# YTM32B1MD2 register map
Vendor: YTMicro; File version: 1.0
CPU: CM33 r0p4, little endian, MPU, FPU, 2 interrupt priority bits
Registers are 32-bit, read-write, reset 0x0 unless marked. A register's access mark holds for its fields unless they carry their own. Offsets are from the block's base; [hi:lo] are bit positions; {n}, {i} and the like mark numbered series.

## MPWM0 — Multiple Pulse Width Modulation
Base 0x4004F000; register names take the prefix MPWM0_
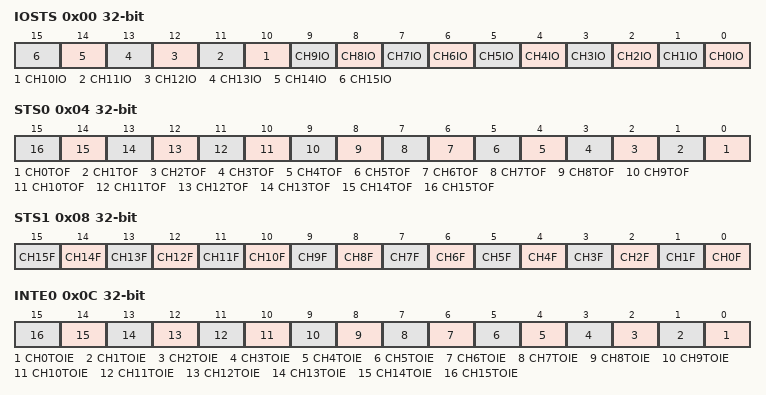
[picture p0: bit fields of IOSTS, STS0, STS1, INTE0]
0x00 IOSTS ro
  [all] fields
    0=Channel status is 0; 1=Channel status is 1
  [n] CH{n}IO (n=0..15) — Indicate channel {n} input/output status in pwm mode, compare mode and input capture mode. This bit is read only and the write operation is invalid.
0x04 STS0
  [all] fields
    0=No timer overflow event occurs; 1=Timer overflow event occurs
  [n] CH{n}TOF (n=0..15) — Indicate channel {n} timer overflow flag. Write 1 to clear the bit.
0x08 STS1
  [all] fields
    0=No channel event occurs; 1=Channel event occurs
  [n] CH{n}F (n=0..15) — Indicate channel {n} matching event flag in common timer mode, pwm mode, compare mode and pulse counter mode. Indicate channel {n} capture event flag in input capture mode. Write 1 to clear the bit.
0x0C INTE0
  [n] CH{n}TOIE (n=0..15) — Channel {n} timer overflow interrupt enable/disable.
    0=Channel {n} timer overflow interrupt is disabled; 1=Channel {n} timer overflow interrupt is enabled
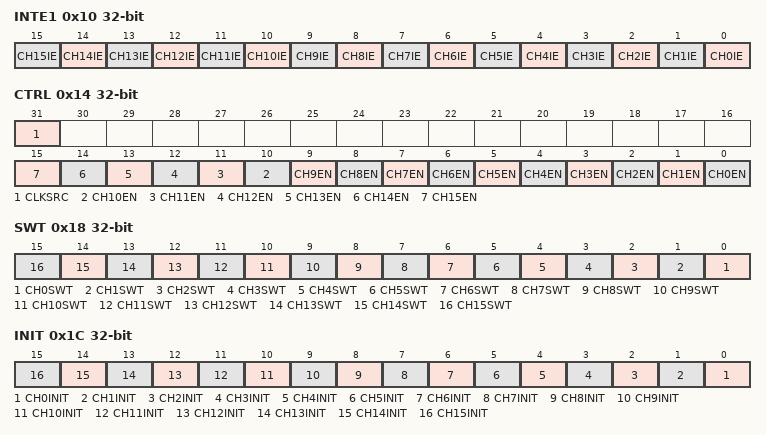
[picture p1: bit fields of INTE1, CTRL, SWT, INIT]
0x10 INTE1
  [n] CH{n}IE (n=0..15) — Channel {n} interrupt enable/disable.
    0=Channel {n} interrupt is disabled; 1=Channel {n} interrupt is enabled
0x14 CTRL
  [31] CLKSRC — Select MPWM works in function clock or bus clock domain.
    0=Using bus clock as the MPWM module clock source; 1=Using function clock(from IPC) as the MPWM module clock source
  [n] CH{n}EN (n=0..15) — Channel {n} enable/disable.
    0=Channel {n} is disabled; 1=Channel {n} is enabled
0x18 SWT wo
  [n] CH{n}SWT (n=0..15) — Channel {n} software trigger by writing 1 to this bit and keep a bus clock cycle. The bit is write only. Read operation is invalid and always returns 0.
0x1C INIT
  [n] CH{n}INIT (n=0..15) — Channel {n} initial value in PWM mode and compare mode before Channel {n} is enabled.
    0=Channel {n} initial value is 0; 1=Channel {n} initial value is 1
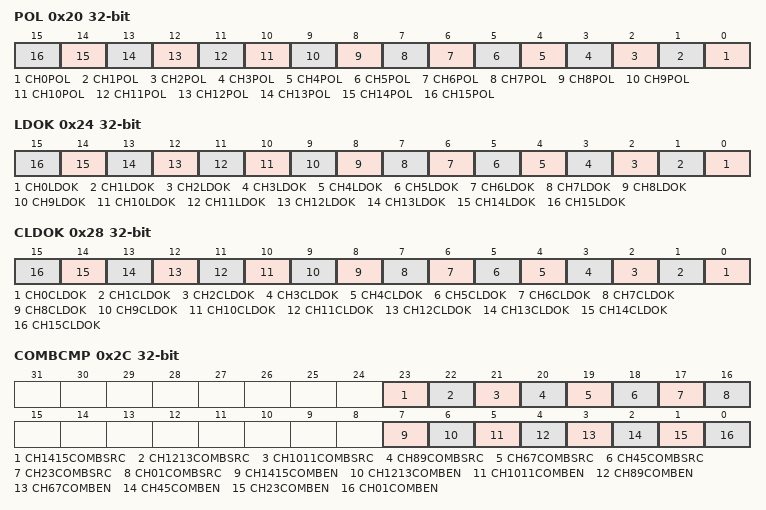
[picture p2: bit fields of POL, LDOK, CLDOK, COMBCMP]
0x20 POL
  [n] CH{n}POL (n=0..15) — Channel {n} polarity in PWM mode and compare mode.
    0=Not invert the channel {n} output; 1=Invert the channel {n} output
0x24 LDOK
  [all] fields
    0=Registers is not ready for loading; 1=Registers is ready for loading and wait for loading opportunity
  [n] CH{n}LDOK (n=0..15) — Set CH{n}LDOK to indicate registers(CMP and PERIOD) is ready for loading, it is cleared automatically when registers load successfully.
0x28 CLDOK
  [n] CH{n}CLDOK (n=0..15) — Write 1 to this bit to clear CH{n}LDOK, and it automatically clear when CH{n}LDOK=0.
0x2C COMBCMP
  [23] CH1415COMBSRC — When CH1415COMBSRC=0, select channel 14 as combination capture input source. When CH1415COMBSRC=1, select channel 15 as combination capture input source.
  [22] CH1213COMBSRC — When CH1213COMBSRC=0, select channel 12 as combination capture input source. When CH1213COMBSRC=1, select channel 13 as combination capture input source.
  [21] CH1011COMBSRC — When CH1011COMBSRC=0, select channel 10 as combination capture input source. When CH1011COMBSRC=1, select channel 11 as combination capture input source.
  [20] CH89COMBSRC — When CH89COMBSRC=0, select channel 8 as combination capture input source. When CH89COMBSRC=1, select channel 9 as combination capture input source.
  [19] CH67COMBSRC — When CH67COMBSRC=0, select channel 6 as combination capture input source. When CH67COMBSRC=1, select channel 7 as combination capture input source.
  [18] CH45COMBSRC — When CH45COMBSRC=0, select channel 4 as combination capture input source. When CH45COMBSRC=1, select channel 5 as combination capture input source.
  [17] CH23COMBSRC — When CH23COMBSRC=0, select channel 2 as combination capture input source. When CH23COMBSRC=1, select channel 3 as combination capture input source.
  [16] CH01COMBSRC — When CH01COMBSRC=0, select channel 0 as combination capture input source. When CH01COMBSRC=1, select channel 1 as combination capture input source.
  [7] CH1415COMBEN — When CH1415COMBEN=1, pulse capture is realized by channel 14 and channel 15 combination. Channel 14 and channel 15 need to be configured separately.
  [6] CH1213COMBEN — When CH1213COMBEN=1, pulse capture is realized by channel 12 and channel 13 combination. Channel 12 and channel 13 need to be configured separately.
  [5] CH1011COMBEN — When CH1011COMBEN=1, pulse capture is realized by channel 10 and channel 11 combination. Channel 10 and channel 11 need to be configured separately.
  [4] CH89COMBEN — When CH89COMBEN=1, pulse capture is realized by channel 8 and channel 9 combination. Channel 8 and channel 9 need to be configured separately.
  [3] CH67COMBEN — When CH67COMBEN=1, pulse capture is realized by channel 6 and channel 7 combination. Channel 6 and channel 7 need to be configured separately.
  [2] CH45COMBEN — When CH45COMBEN=1, pulse capture is realized by channel 4 and channel 5 combination. Channel 4 and channel 5 need to be configured separately.
  [1] CH23COMBEN — When CH23COMBEN=1, pulse capture is realized by channel 2 and channel 3 combination. Channel 2 and channel 3 need to be configured separately.
  [0] CH01COMBEN — When CH01COMBEN=1, pulse capture is realized by channel 0 and channel 1 combination. Channel 0 and channel 1 need to be configured separately.
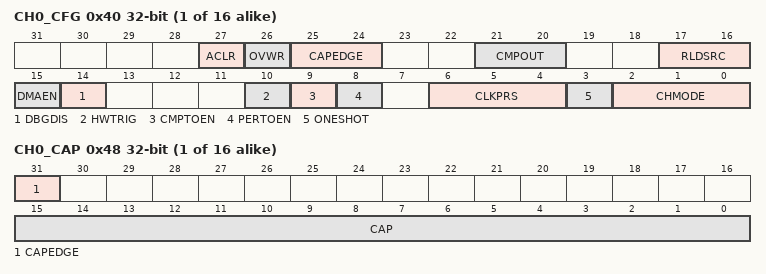
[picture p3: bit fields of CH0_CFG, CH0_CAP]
{0x40+0x20*i} CH{i}_CFG (i=0..15)
  [27] ACLR — Counter is automatically reset to 0 when capture event occurs.
    0=Auto clear is disabled; 1=Auto clear is enabled
  [26] OVWR — Over write the CAP register from counter when new capture event occurs.
    0=Over write is disabled; 1=Over write is enabled
  [25:24] CAPEDGE — Select the capture edge in the input capture mode.
    0=Capture is disabled; 1=Capture rising edge; 2=Capture falling edge; 3=Capture both rising edge and falling edge
  [21:20] CMPOUT — Select the output value when counter matches with CMP in compare mode.
    0=Compare Output disabled; 1=Output value 0; 2=Output value 1; 3=Output value toggle
  [17:16] RLDSRC — Double Buffer Registers reloading sources.
    0=PERIOD matching point reload; 1=Hardware trigger point reload; 2=Software trigger point reload; 3=Double buffer mechanism is disabled
  [15] DMAEN — When DMA is enabled and STS1[CHxF] is set, generate a DMA request.
    0=DMA request is disabled; 1=DMA request is enabled
  [14] DBGDIS — Enable/disable the debug mode.
    0=Counter stops under debug mode; 1=Counter keeps running under debug mode
  [10] HWTRIG — Hardware trigger enable/disable.
    0=Hardware trigger is disabled; 1=Hardware trigger is enabled
  [9] CMPTOEN — Registers CMP matching trigger output enable/disable.
    0=Registers CMP matching trigger output is disabled; 1=Registers CMP matching trigger output is enabled
  [8] PERTOEN — Registers PERIOD matching trigger output enable/disable.
    0=Registers PERIOD matching trigger output is disabled; 1=Registers PERIOD matching trigger output is enabled
  [6:4] CLKPRS — Clock prescaler for counter.
    0=Divide by 1; 1=Divide by 2; 2=Divide by 4; 3=Divide by 8; 4=Divide by 16; 5=Divide by 32; 6=Divide by 64; 7=Divide by 128
  [3] ONESHOT — Counter counting mode.
    0=Continuous mode; 1=One shot mode
  [2:0] CHMODE — Channel mode.
    0=Common timer; 1=PWM mode; 2=Output compare mode; 3=Input capture mode; 4=Pulse counter mode; 5=Center-Aligned PWM mode
{0x44+0x20*i} CH{i}_CNT ro (i=0..15)
  [15:0] CNT rw — Reading this register gets the counter value, and writing to this register is invalid.
{0x48+0x20*i} CH{i}_CAP ro (i=0..15)
  [31] CAPEDGE rw — In capture mode, store generate capture event edge information.
    0=Capture event occurs on the falling edge; 1=Capture event occurs on the rising edge
  [15:0] CAP rw — In capture mode, store counter value when a capture event occurs.
{0x50+0x20*i} CH{i}_PERIOD (i=0..15)
  [15:0] PERIOD — Counter counting period.
{0x54+0x20*i} CH{i}_CMP (i=0..15)
  [15:0] CMP — Counter compare value.
